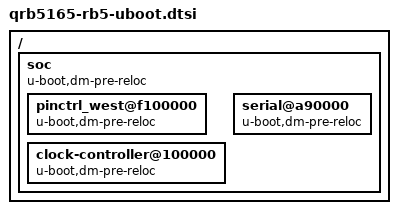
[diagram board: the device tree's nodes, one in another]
// SPDX-License-Identifier: GPL-2.0+
/*
 * U-Boot addition to handle QRB5165-RB5 pre-relocation devices
 *
 * (C) Copyright 2023 Bhupesh Sharma <bhupesh.sharma@linaro.org>
 */

/ {
	soc {
		u-boot,dm-pre-reloc;

		pinctrl_west@f100000 {
			u-boot,dm-pre-reloc;
		};

		clock-controller@100000 {
			u-boot,dm-pre-reloc;
		};

		serial@a90000 {
			u-boot,dm-pre-reloc;
		};
	};
};
